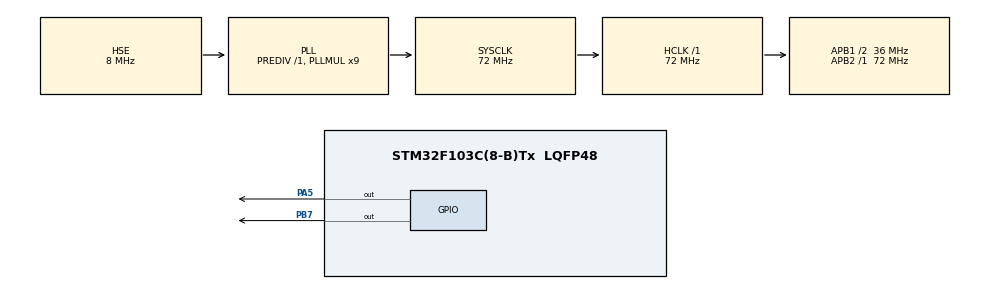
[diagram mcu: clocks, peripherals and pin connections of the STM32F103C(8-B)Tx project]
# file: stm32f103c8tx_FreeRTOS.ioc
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FREERTOS.Tasks01=defaultTask,24,128,StartDefaultTask,Default,NULL,Dynamic,NULL,NULL
Mcu.Family=STM32F1
Mcu.Name=STM32F103C(8-B)Tx
Mcu.Package=LQFP48
NVIC.PriorityGroup=NVIC_PRIORITYGROUP_4
NVIC.TIM1_UP_IRQn=true\:15\:0\:false\:false\:true\:false\:false\:true\:true
NVIC.TimeBase=TIM1_UP_IRQn
NVIC.TimeBaseIP=TIM1
PA13.Mode=Serial_Wire
PA13.Signal=SYS_JTMS-SWDIO
PA14.Mode=Serial_Wire
PA14.Signal=SYS_JTCK-SWCLK
PA5.Signal=GPIO_Output
PB7.Signal=GPIO_Output
PC14-OSC32_IN.Mode=LSE-External-Oscillator
PC14-OSC32_IN.Signal=RCC_OSC32_IN
PC15-OSC32_OUT.Mode=LSE-External-Oscillator
PC15-OSC32_OUT.Signal=RCC_OSC32_OUT
PD0-OSC_IN.Mode=HSE-External-Oscillator
PD0-OSC_IN.Signal=RCC_OSC_IN
PD1-OSC_OUT.Mode=HSE-External-Oscillator
PD1-OSC_OUT.Signal=RCC_OSC_OUT
ProjectManager.HeapSize=0x200
ProjectManager.StackSize=0x400
ProjectManager.TargetToolchain=MDK-ARM V5.32
RCC.AHBFreq_Value=72000000
RCC.APB1CLKDivider=RCC_HCLK_DIV2
RCC.APB1Freq_Value=36000000
RCC.APB1TimFreq_Value=72000000
RCC.APB2Freq_Value=72000000
RCC.APB2TimFreq_Value=72000000
RCC.HCLKFreq_Value=72000000
RCC.PLLMUL=RCC_PLL_MUL9
RCC.PLLSourceVirtual=RCC_PLLSOURCE_HSE
RCC.SYSCLKFreq_VALUE=72000000
RCC.SYSCLKSource=RCC_SYSCLKSOURCE_PLLCLK
RCC.USBFreq_Value=72000000
VP_FREERTOS_VS_CMSIS_V2.Mode=CMSIS_V2
VP_SYS_VS_tim1.Mode=TIM1
board=custom

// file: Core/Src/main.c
/* USER CODE BEGIN Header */
/**
  ******************************************************************************
  * @file           : main.c
  * @brief          : Main program body
  ******************************************************************************
  * @attention
  *
  * Copyright (c) 2024 STMicroelectronics.
  * All rights reserved.
  *
  * This software is licensed under terms that can be found in the LICENSE file
  * in the root directory of this software component.
  * If no LICENSE file comes with this software, it is provided AS-IS.
  *
  ******************************************************************************
  */
/* USER CODE END Header */
#include "main.h"
#include "cmsis_os.h"
#include "gpio.h"

void SystemClock_Config(void);
void MX_FREERTOS_Init(void);

int main(void)
{

  /* MCU Configuration--------------------------------------------------------*/

  /* Reset of all peripherals, Initializes the Flash interface and the Systick. */
  HAL_Init();

  /* Configure the system clock */
  SystemClock_Config();

  /* Initialize all configured peripherals */
  MX_GPIO_Init();
  /* USER CODE BEGIN 2 */
  IIC_GPIO_Init();
  OLED_init();
  OLED_clear();
  MPU_Init();
  HAL_Delay(500);
  MPU_DMP_Init();
  HAL_Delay(500);
  OLED_showString(2, 1, "pitch:");
  OLED_showString(3, 1, "roll:");
  OLED_showString(4, 1, "yaw:");
  /* USER CODE END 2 */

  /* Init scheduler */
  osKernelInitialize();

  /* Call init function for freertos objects (in cmsis_os2.c) */
  MX_FREERTOS_Init();

  /* Start scheduler */
  osKernelStart();

  /* We should never get here as control is now taken by the scheduler */

  /* Infinite loop */
  while (1)
  {

  }
}

void SystemClock_Config(void)
{
  RCC_OscInitTypeDef RCC_OscInitStruct = {0};
  RCC_ClkInitTypeDef RCC_ClkInitStruct = {0};

  /** Initializes the RCC Oscillators according to the specified parameters
  * in the RCC_OscInitTypeDef structure.
  */
  RCC_OscInitStruct.OscillatorType = RCC_OSCILLATORTYPE_HSE;
  RCC_OscInitStruct.HSEState = RCC_HSE_ON;
  RCC_OscInitStruct.HSEPredivValue = RCC_HSE_PREDIV_DIV1;
  RCC_OscInitStruct.HSIState = RCC_HSI_ON;
  RCC_OscInitStruct.PLL.PLLState = RCC_PLL_ON;
  RCC_OscInitStruct.PLL.PLLSource = RCC_PLLSOURCE_HSE;
  RCC_OscInitStruct.PLL.PLLMUL = RCC_PLL_MUL9;
  if (HAL_RCC_OscConfig(&RCC_OscInitStruct) != HAL_OK)
  {
    Error_Handler("HAL_RCC_OscConfig init erro");
  }

  /** Initializes the CPU, AHB and APB buses clocks
  */
  RCC_ClkInitStruct.ClockType = RCC_CLOCKTYPE_HCLK|RCC_CLOCKTYPE_SYSCLK
                              |RCC_CLOCKTYPE_PCLK1|RCC_CLOCKTYPE_PCLK2;
  RCC_ClkInitStruct.SYSCLKSource = RCC_SYSCLKSOURCE_PLLCLK;
  RCC_ClkInitStruct.AHBCLKDivider = RCC_SYSCLK_DIV1;
  RCC_ClkInitStruct.APB1CLKDivider = RCC_HCLK_DIV2;
  RCC_ClkInitStruct.APB2CLKDivider = RCC_HCLK_DIV1;

  if (HAL_RCC_ClockConfig(&RCC_ClkInitStruct, FLASH_LATENCY_2) != HAL_OK)
  {
    Error_Handler("HAL_RCC_ClockConfig init erro");
  }
}

void HAL_TIM_PeriodElapsedCallback(TIM_HandleTypeDef *htim)
{
  if (htim->Instance == TIM1) {
    HAL_IncTick();
  }
}

void Error_Handler(char *ErroMessage)
{
  __disable_irq();
  while (1)
  {
  }
}

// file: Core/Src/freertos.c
/* USER CODE BEGIN Header */
/**
  ******************************************************************************
  * File Name          : freertos.c
  * Description        : Code for freertos applications
  ******************************************************************************
  * @attention
  *
  * Copyright (c) 2024 STMicroelectronics.
  * All rights reserved.
  *
  * This software is licensed under terms that can be found in the LICENSE file
  * in the root directory of this software component.
  * If no LICENSE file comes with this software, it is provided AS-IS.
  *
  ******************************************************************************
  */
/* USER CODE END Header */

#include "FreeRTOS.h"
#include "task.h"
#include "main.h"
#include "cmsis_os.h"

/* USER CODE BEGIN Includes */
#include "OLED.h"
#include "MPU6050.h"
#include "motor_control.h"
/* USER CODE END Includes */

/* USER CODE BEGIN Variables */

static MPU6050_Data_Struct MPU_Data;
static int16_t encoder_left,encoder_right;

/* USER CODE END Variables */
/* Definitions for Task_MPU_5ms */
osThreadId_t Task_MPU_5msHandle;
const osThreadAttr_t Task_MPU_5ms_attributes = {
  .name = "Task_MPU_5ms",
  .stack_size = 128 * 4,
  .priority = (osPriority_t) osPriorityHigh,
};
/* Definitions for Task_PID_20ms */
osThreadId_t Task_PID_20msHandle;
const osThreadAttr_t Task_PID_20ms_attributes = {
  .name = "Task_PID_20ms",
  .stack_size = 128 * 4,
  .priority = (osPriority_t) osPriorityNormal,
};
/* Definitions for Task_OLED_50ms */
osThreadId_t Task_OLED_50msHandle;
const osThreadAttr_t Task_OLED_50ms_attributes = {
  .name = "Task_OLED_50ms",
  .stack_size = 128 * 4,
  .priority = (osPriority_t) osPriorityLow,
};
/* USER CODE BEGIN FunctionPrototypes */
void StartTask_MPU_5ms(void *argument);
void StartTask_PID_20ms(void *argument);
void StartTask_OLED_50ms(void *argument);

/* USER CODE END FunctionPrototypes */

void MX_FREERTOS_Init(void); /* (MISRA C 2004 rule 8.1) */

void MX_FREERTOS_Init(void) {

  /* Create the thread(s) */
  /* creation of Task_MPU_5ms */
  Task_MPU_5msHandle = osThreadNew(StartTask_MPU_5ms, NULL, &Task_MPU_5ms_attributes);

  /* creation of Task_PID_20ms */
  //Task_PID_20msHandle = osThreadNew(StartTask_PID_20ms, NULL, &Task_PID_20ms_attributes);

  /* creation of Task_OLED_50ms */
  Task_OLED_50msHandle = osThreadNew(StartTask_OLED_50ms, NULL, &Task_OLED_50ms_attributes);

}

void StartTask_MPU_5ms(void *argument)
{
  /* USER CODE BEGIN StartDefaultTask */
  /* Infinite loop */
  for(;;)
  {
		while (MPU_GetData(&MPU_Data)) {}
		MPU_Get_Accelerometer(&MPU_Data);
		MPU_Get_Gyroscope(&MPU_Data);
		//encoder_left=Motor_getSpeed(MOTOR_A);
		//encoder_right=Motor_getSpeed(MOTOR_B);//读取encode_left, encode_right，读取的周期就是本函数的运行周期，不需要额外设置
		osDelay(20);
  }
  /* USER CODE END StartDefaultTask */
}

void StartTask_PID_20ms(void *argument)
{
  /* USER CODE BEGIN StartDefaultTask */
  /* Infinite loop */
  for(;;)
  {

	static uint32_t Balance_Pwm;
	static float Velocity_Pwm,Turn_Pwm;

    Balance_Pwm =  Motor_verticalRingPD(MPU_Data.pitch,  MPU_Data.gyro_y); //平衡环PD计算
    Velocity_Pwm = Motor_verticalSpeedPI( encoder_left,  encoder_right,MPU_Data.pitch, 10.0);//速度环PI计算
    Turn_Pwm = Motor_verticalTurnPD(0,MPU_Data.yaw,  MPU_Data.gyro_z);//转向环PD计算
    int Moto1 = Balance_Pwm - Velocity_Pwm + Turn_Pwm;//计算左轮电机所需PWM
    int Moto2 = Balance_Pwm - Velocity_Pwm - Turn_Pwm;//计算右轮电机所需PWM
    Motor_PWMLimiting(&Moto1,&Moto2);//对最终给两个电机的PWM进行限幅
	if(MPU_Data.pitch < -40 || MPU_Data.pitch > 40) 			{Moto1=0;Moto2=0;}
    Motor_setSpeed(MOTOR_A,Moto1);
	Motor_setSpeed(MOTOR_B,Moto2);
		osDelay(20);
  }
  /* USER CODE END StartDefaultTask */
}
void StartTask_OLED_50ms(void *argument)
{
  /* USER CODE BEGIN StartDefaultTask */
  /* Infinite loop */
  for(;;)
  {
	    OLED_showSignedNum(2, 8, MPU_Data.pitch, 3);
		OLED_showSignedNum(3, 8, MPU_Data.roll , 3);
		OLED_showSignedNum(4, 8, MPU_Data.yaw, 3);
		osDelay(100);
  }
  /* USER CODE END StartDefaultTask */
}
